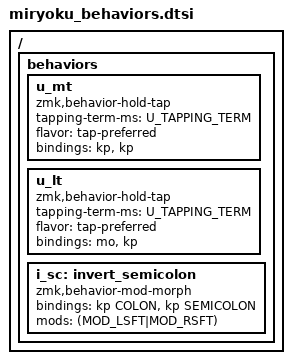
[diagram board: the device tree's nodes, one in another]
// Copyright 2022 Manna Harbour
// https://github.com/manna-harbour/miryoku

/ {
  behaviors {
    u_mt: u_mt {
      compatible = "zmk,behavior-hold-tap";
      #binding-cells = <2>;
      tapping-term-ms = <U_TAPPING_TERM>;
      flavor = "tap-preferred";
      bindings = <&kp>, <&kp>;
    };
    u_lt: u_lt {
      compatible = "zmk,behavior-hold-tap";
      #binding-cells = <2>;
      tapping-term-ms = <U_TAPPING_TERM>;
      flavor = "tap-preferred";
      bindings = <&mo>, <&kp>;
    };
    i_sc: invert_semicolon {
        compatible = "zmk,behavior-mod-morph";
        #binding-cells = <0>;
        bindings = <&kp COLON>, <&kp SEMICOLON>;
        mods = <(MOD_LSFT|MOD_RSFT)>;
    };
  };
};
